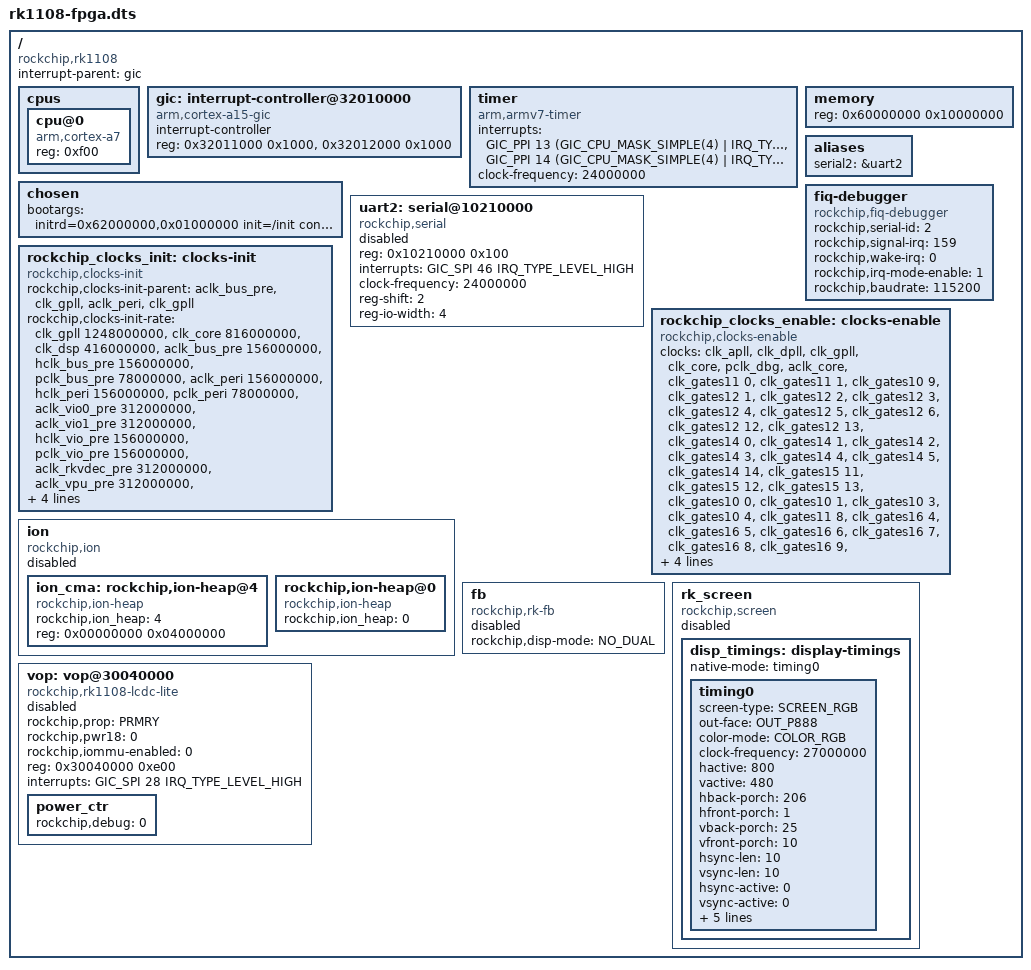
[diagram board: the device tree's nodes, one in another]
/dts-v1/;

#include <dt-bindings/interrupt-controller/arm-gic.h>
#include "skeleton.dtsi"
#include "rk1108-clocks.dtsi"
#include <dt-bindings/rkfb/rk_fb.h>

/ {
	compatible = "rockchip,rk1108";
	interrupt-parent = <&gic>;

	cpus {
		#address-cells = <1>;
		#size-cells = <0>;

		cpu@0 {
			device_type = "cpu";
			compatible = "arm,cortex-a7";
			reg = <0xf00>;
		};
	};

	gic: interrupt-controller@32010000 {
		compatible = "arm,cortex-a15-gic";
		interrupt-controller;
		#interrupt-cells = <3>;
		#address-cells = <0>;
		reg = <0x32011000 0x1000>,
		      <0x32012000 0x1000>;
	};

	timer {
		compatible = "arm,armv7-timer";
		interrupts = <GIC_PPI 13
			      (GIC_CPU_MASK_SIMPLE(4) | IRQ_TYPE_LEVEL_HIGH)>,
			     <GIC_PPI 14
			      (GIC_CPU_MASK_SIMPLE(4) | IRQ_TYPE_LEVEL_HIGH)>;
		clock-frequency = <24000000>;
	};

	memory {
		device_type = "memory";
		reg = <0x60000000 0x10000000>;
	};

	chosen {
		bootargs = "initrd=0x62000000,0x01000000 init=/init console=ttyFIQ0,115200 earlyprintk=uart8250-32bit,0x10210000 clk_ignore_unused";
	};

	aliases {
		serial2 = &uart2;
	};

	uart2: serial@10210000 {
		compatible = "rockchip,serial";
		reg = <0x10210000 0x100>;
		interrupts = <GIC_SPI 46 IRQ_TYPE_LEVEL_HIGH>;
		clock-frequency = <24000000>;
//		clocks = <&xin24m>, <&xin24m>;
//		clock-names = "sclk_uart", "pclk_uart";
		reg-shift = <2>;
		reg-io-width = <4>;
		status = "disabled";
	};

	fiq-debugger {
		compatible = "rockchip,fiq-debugger";
		rockchip,serial-id = <2>;
		rockchip,signal-irq = <159>;
		rockchip,wake-irq = <0>;
		rockchip,irq-mode-enable = <1>;  /* If enable uart uses irq instead of fiq */
		rockchip,baudrate = <115200>;  /* Only 115200 and 1500000 */
	};

	rockchip_clocks_init: clocks-init{
		compatible = "rockchip,clocks-init";
		rockchip,clocks-init-parent =
			<&aclk_bus_pre &clk_gpll>, <&aclk_peri &clk_gpll>;
		rockchip,clocks-init-rate =
			<&clk_gpll 1248000000>, <&clk_core 816000000>,
			<&clk_dsp 416000000>, <&aclk_bus_pre 156000000>,
			<&hclk_bus_pre 156000000>, <&pclk_bus_pre 78000000>,
			<&aclk_peri 156000000>, <&hclk_peri 156000000>,
			<&pclk_peri 78000000>, <&aclk_vio0_pre 312000000>,
			<&aclk_vio1_pre 312000000>, <&hclk_vio_pre 156000000>,
			<&pclk_vio_pre 156000000>, <&aclk_rkvdec_pre 312000000>,
			<&aclk_vpu_pre 312000000>, <&clk_hevc_cabac 312000000>,
			<&clk_hevc_core 312000000>, <&aclk_rkvenc_pre 312000000>,
			<&clk_venc_core 312000000>;
	};

	rockchip_clocks_enable: clocks-enable {
		compatible = "rockchip,clocks-enable";
		clocks =
			/*PLL*/
			<&clk_apll>,
			<&clk_dpll>,
			<&clk_gpll>,

			/*PD_CORE*/
			<&clk_core>,
			<&pclk_dbg>,
			<&aclk_core>,
			<&clk_gates11 0>,/*aclk_core_niu*/
			<&clk_gates11 1>,/*pclk_core_niu*/
			<&clk_gates10 9>,/*clk_ddrphy4x*/

			/*PD_BUS*/
			<&clk_gates12 1>,/*clk_intmem0*/
			<&clk_gates12 2>,/*aclk_dmac_bus*/
			<&clk_gates12 3>,/*hclk_rom*/
			<&clk_gates12 4>,/*pclk_ddr_upctl*/
			<&clk_gates12 5>,/*clk_ddr_upctl*/
			<&clk_gates12 6>,/*pclk_ddrmon*/
			<&clk_gates12 12>,/*pclk_efuse0*/
			<&clk_gates12 13>,/*pclk_efuse1*/
			<&clk_gates14 0>,/*pclk_grf*/
			<&clk_gates14 1>,/*aclk_niu*/
			<&clk_gates14 2>,/*pclk_mschniu*/
			<&clk_gates14 3>,/*pclk_top_niu*/
			<&clk_gates14 4>,/*pclk_ddrphy*/
			<&clk_gates14 5>,/*pclk_cru*/
			<&clk_gates14 14>,/*pclk_usbgrf*/

			/*PD_PERI*/
			<&clk_gates15 11>,/*aclk_peri_niu*/
			<&clk_gates15 12>,/*hclk_peri_niu*/
			<&clk_gates15 13>,/*pclk_peri_niu*/

			/*PD_PMU*/
			<&clk_gates10 0>,/*pclk_pmu*/
			<&clk_gates10 1>,/*pclk_intmem1*/
			<&clk_gates10 3>,/*pclk_pmugrf*/
			<&clk_gates10 4>,/*pclk_pmu_niu*/

			/*PD_DSP*/
			<&clk_gates11 8>,/*aclk_dsp_edp_perf*/
			<&clk_gates16 4>,/*pclk_dsp_iop_niu*/
			<&clk_gates16 5>,/*aclk_dsp_epp_niu*/
			<&clk_gates16 6>,/*aclk_dsp_edp_niu*/
			<&clk_gates16 7>,/*pclk_dsp_dbg_niu*/
			<&clk_gates16 8>,/*pclk_dsp_cfg_niu*/
			<&clk_gates16 9>,/*pclk_ceva_pfm_mon*/
			<&clk_gates16 14>,/*aclk_dsp_edap_niu*/
			<&clk_gates16 15>,/*aclk_dsp_epp_perf*/

			/*PD_VIDEO*/
			<&clk_gates19 4>,/*aclk_rkvdec_niu*/
			<&clk_gates19 5>,/*hclk_rkvdec_niu*/
			<&clk_gates19 6>,/*aclk_vpu_niu*/
			<&clk_gates19 10>,/*hclk_rkvenc_niu*/
			<&clk_gates19 11>,/*aclk_rkvenc_niu*/

			<&clk_gates1 9>, /* clk_timer0 */
			<&clk_gates1 10>, /* clk_timer1 */

			<&clk_gates0 3>;/*clk_jtag*/
	};

	ion {
		status = "disabled";
		compatible = "rockchip,ion";
		#address-cells = <1>;
		#size-cells = <0>;

		ion_cma: rockchip,ion-heap@4 { /* CMA HEAP */
			compatible = "rockchip,ion-heap";
			rockchip,ion_heap = <4>;
			reg = <0x00000000 0x04000000>; /* 64MB */
		};
		rockchip,ion-heap@0 { /* VMALLOC HEAP */
			compatible = "rockchip,ion-heap";
			rockchip,ion_heap = <0>;
		};
	};

	fb: fb {
		status = "disabled";
		compatible = "rockchip,rk-fb";
		rockchip,disp-mode = <NO_DUAL>;
	};

	rk_screen: rk_screen {
		status = "disabled";
		compatible = "rockchip,screen";
		disp_timings: display-timings {
			native-mode = <&timing0>;
			timing0: timing0 {
				screen-type = <SCREEN_RGB>;
				out-face    = <OUT_P888>;
				color-mode = <COLOR_RGB>;
				clock-frequency = <27000000>;
				hactive = <800>;
				vactive = <480>;
				hback-porch = <206>;
				hfront-porch = <1>;
				vback-porch = <25>;
				vfront-porch = <10>;
				hsync-len = <10>;
				vsync-len = <10>;
				hsync-active = <0>;
				vsync-active = <0>;
				de-active = <0>;
				pixelclk-active = <0>;
				swap-rb = <0>;
				swap-rg = <0>;
				swap-gb = <0>;
			};
		};
	};

	vop: vop@30040000 {
		status = "disabled";
		compatible = "rockchip,rk1108-lcdc-lite";
		rockchip,prop = <PRMRY>;
		rockchip,pwr18 = <0>;
		rockchip,iommu-enabled = <0>;
		reg = <0x30040000 0xe00>;
		interrupts = <GIC_SPI 28 IRQ_TYPE_LEVEL_HIGH>;
		/*clocks = <&dummy>, <&dummy>, <&dummy>;
		clock-names = "aclk_lcdc", "dclk_lcdc", "hclk_lcdc";*/
		power_ctr: power_ctr {
			rockchip,debug = <0>;
			/*
			lcd_en:lcd_en {
				rockchip,power_type = <GPIO>;
				gpios = <&gpio7 GPIO_A3 GPIO_ACTIVE_HIGH>;
				rockchip,delay = <10>;
			};
			*/
			/*lcd_cs:lcd_cs {
				rockchip,power_type = <REGULATOR>;
				rockchip,delay = <10>;
			};

			lcd_rst:lcd_rst {
				rockchip,power_type = <GPIO>;
				gpios = <&gpio3 GPIO_D6 GPIO_ACTIVE_HIGH>;
				rockchip,delay = <5>;
			};*/
		};
	};
};
